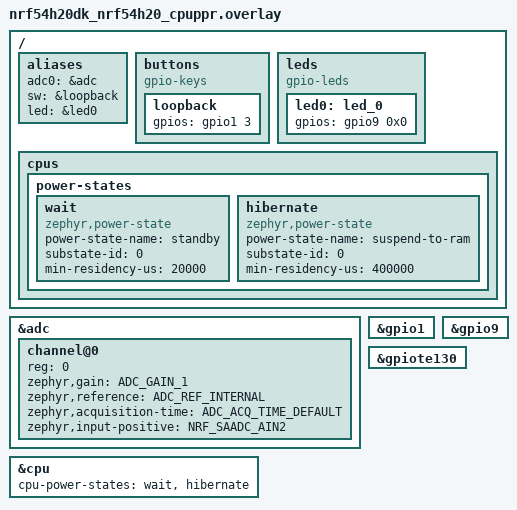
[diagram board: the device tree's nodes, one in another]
/*
 * Copyright (c) 2025 Nordic Semiconductor ASA
 *
 * SPDX-License-Identifier: LicenseRef-Nordic-5-Clause
 */

/* Required GPIO loopback: P1.02 - P1.03 */
/ {
	aliases {
		adc0 = &adc;
		sw = &loopback;
		led = &led0;
	};

	buttons {
		compatible = "gpio-keys";

		loopback: loopback {
			gpios = <&gpio1 3 GPIO_ACTIVE_HIGH>;
		};
	};

	leds {
		compatible = "gpio-leds";

		led0: led_0 {
			gpios = < &gpio9 0x0 0x0 >;
		};
	};

	cpus {
		power-states {
			wait: wait {
				compatible = "zephyr,power-state";
				power-state-name = "standby";
				substate-id = <0>;
				min-residency-us = <20000>;
			};

			hibernate: hibernate {
				compatible = "zephyr,power-state";
				power-state-name = "suspend-to-ram";
				substate-id = <0>;
				min-residency-us = <400000>;
			};
		};
	};
};

&adc {
	#address-cells = <1>;
	#size-cells = <0>;
	status = "okay";

	channel@0 {
		reg = <0>;
		zephyr,gain = "ADC_GAIN_1";
		zephyr,reference = "ADC_REF_INTERNAL";
		zephyr,acquisition-time = <ADC_ACQ_TIME_DEFAULT>;
		zephyr,input-positive = <NRF_SAADC_AIN2>;
	};
};

&cpu {
	cpu-power-states = <&wait &hibernate>;
};

&gpio1 {
	status = "okay";
};

&gpio9 {
	status = "okay";
};

&gpiote130 {
	status = "okay";
};
